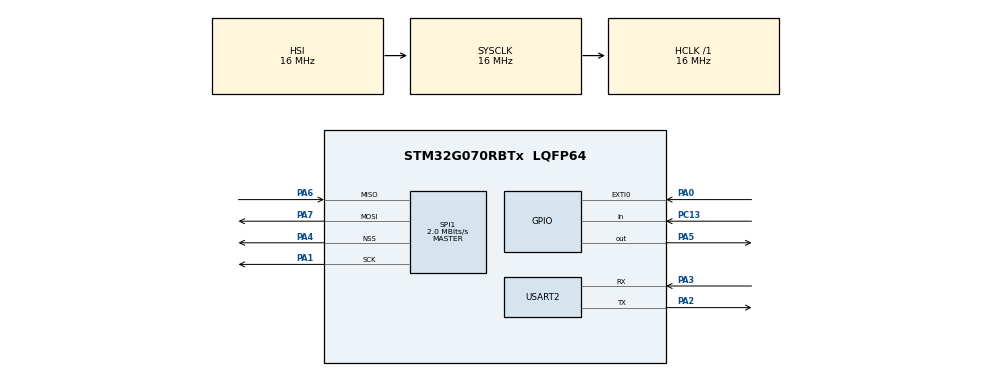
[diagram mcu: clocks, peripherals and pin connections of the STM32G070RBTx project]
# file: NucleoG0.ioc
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Dma.Request0=SPI1_TX
Dma.SPI1_TX.0.Direction=DMA_MEMORY_TO_PERIPH
Dma.SPI1_TX.0.EventEnable=DISABLE
Dma.SPI1_TX.0.Instance=DMA1_Channel1
Dma.SPI1_TX.0.MemDataAlignment=DMA_MDATAALIGN_BYTE
Dma.SPI1_TX.0.MemInc=DMA_MINC_ENABLE
Dma.SPI1_TX.0.Mode=DMA_NORMAL
Dma.SPI1_TX.0.PeriphDataAlignment=DMA_PDATAALIGN_BYTE
Dma.SPI1_TX.0.PeriphInc=DMA_PINC_DISABLE
Dma.SPI1_TX.0.Polarity=HAL_DMAMUX_REQ_GEN_RISING
Dma.SPI1_TX.0.Priority=DMA_PRIORITY_LOW
Dma.SPI1_TX.0.RequestNumber=1
Dma.SPI1_TX.0.SignalID=NONE
Dma.SPI1_TX.0.SyncEnable=DISABLE
Dma.SPI1_TX.0.SyncPolarity=HAL_DMAMUX_SYNC_NO_EVENT
Dma.SPI1_TX.0.SyncRequestNumber=1
Dma.SPI1_TX.0.SyncSignalID=NONE
FREERTOS.INCLUDE_xQueueGetMutexHolder=1
FREERTOS.INCLUDE_xSemaphoreGetMutexHolder=1
FREERTOS.MEMORY_ALLOCATION=0
FREERTOS.Tasks01=defaultTask,0,128,StartDefaultTask,Default,NULL,Dynamic,NULL,NULL
FREERTOS.configTOTAL_HEAP_SIZE=4096
Mcu.Family=STM32G0
Mcu.Name=STM32G070RBTx
Mcu.Package=LQFP64
NVIC.DMA1_Channel1_IRQn=true\:3\:0\:false\:false\:true\:true\:false\:true
NVIC.SPI1_IRQn=true\:3\:0\:false\:false\:true\:true\:true\:true
NVIC.USART2_IRQn=true\:3\:0\:false\:false\:true\:true\:true\:true
PA0.GPIO_PuPd=GPIO_PULLUP
PA0.Signal=GPXTI0
PA1.Mode=Full_Duplex_Master
PA1.Signal=SPI1_SCK
PA2.Mode=Asynchronous
PA2.Signal=USART2_TX
PA3.Mode=Asynchronous
PA3.Signal=USART2_RX
PA4.Mode=NSS_Signal_Hard_Output
PA4.Signal=SPI1_NSS
PA5.Signal=GPIO_Output
PA6.Mode=Full_Duplex_Master
PA6.Signal=SPI1_MISO
PA7.Mode=Full_Duplex_Master
PA7.Signal=SPI1_MOSI
PC13.Signal=GPIO_Input
PC14-OSC32_IN\ (PC14).Mode=LSE-External-Oscillator
PC14-OSC32_IN\ (PC14).Signal=RCC_OSC32_IN
PC15-OSC32_OUT\ (PC15).Mode=LSE-External-Oscillator
PC15-OSC32_OUT\ (PC15).Signal=RCC_OSC32_OUT
PF0-OSC_IN\ (PF0).Mode=HSE-External-Clock-Source
PF0-OSC_IN\ (PF0).Signal=RCC_OSC_IN
ProjectManager.HeapSize=0x200
ProjectManager.StackSize=0x400
ProjectManager.TargetToolchain=STM32CubeIDE
RCC.AHBFreq_Value=16000000
RCC.CortexFreq_Value=16000000
RCC.EXTERNAL_CLOCK_VALUE=48000
RCC.HCLKFreq_Value=16000000
RCC.HSE_VALUE=8000000
RCC.HSI_VALUE=16000000
RCC.SYSCLKFreq_VALUE=16000000
RCC.VCOOutputFreq_Value=128000000
SPI1.BaudRatePrescaler=SPI_BAUDRATEPRESCALER_8
SPI1.CalculateBaudRate=2.0 MBits/s
SPI1.DataSize=SPI_DATASIZE_8BIT
SPI1.Direction=SPI_DIRECTION_2LINES
SPI1.FirstBit=SPI_FIRSTBIT_LSB
SPI1.Mode=SPI_MODE_MASTER
SPI1.VirtualNSS=VM_NSSHARD
SPI1.VirtualType=VM_MASTER
USART2.VirtualMode-Asynchronous=VM_ASYNC
VP_FREERTOS_VS_CMSIS_V1.Mode=CMSIS_V1
VP_SYS_VS_DBSignals.Mode=DisableDeadBatterySignals
board=custom

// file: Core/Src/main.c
/* USER CODE BEGIN Header */
/**
  ******************************************************************************
  * @file           : main.c
  * @brief          : Main program body
  ******************************************************************************
  * @attention
  *
  * <h2><center>&copy; Copyright (c) 2020 STMicroelectronics.
  * All rights reserved.</center></h2>
  *
  * This software component is licensed by ST under BSD 3-Clause license,
  * the "License"; You may not use this file except in compliance with the
  * License. You may obtain a copy of the License at:
  *                        opensource.org/licenses/BSD-3-Clause
  *
  ******************************************************************************
  */
/* USER CODE END Header */

#include "main.h"
#include "cmsis_os.h"

/* USER CODE BEGIN Includes */
#include "application.h"

/* USER CODE END Includes */

/* USER CODE BEGIN PD */
#define LED_GREEN_Pin GPIO_PIN_5
#define LED_GREEN_GPIO_Port GPIOA
/* USER CODE END PD */

SPI_HandleTypeDef hspi1;
DMA_HandleTypeDef hdma_spi1_tx;

UART_HandleTypeDef huart2;

osThreadId defaultTaskHandle;

void SystemClock_Config(void);
static void MX_GPIO_Init(void);
static void MX_DMA_Init(void);
static void MX_USART2_UART_Init(void);
static void MX_SPI1_Init(void);
void StartDefaultTask(void const * argument);

int main(void)
{

  /* MCU Configuration--------------------------------------------------------*/

  /* Reset of all peripherals, Initializes the Flash interface and the Systick. */
  HAL_Init();

  /* Configure the system clock */
  SystemClock_Config();

  /* Initialize all configured peripherals */
  MX_GPIO_Init();
  MX_DMA_Init();
  MX_USART2_UART_Init();
  MX_SPI1_Init();

  /* Create the thread(s) */
  /* definition and creation of defaultTask */
  osThreadDef(defaultTask, StartDefaultTask, osPriorityNormal, 0, 128);
  defaultTaskHandle = osThreadCreate(osThread(defaultTask), NULL);

  /* USER CODE BEGIN RTOS_THREADS */
  application();
  /* add threads, ... */
  /* USER CODE END RTOS_THREADS */

  /* Start scheduler */
  osKernelStart();

  /* We should never get here as control is now taken by the scheduler */
  /* Infinite loop */
  while (1)
  {

  }
}

void SystemClock_Config(void)
{
  RCC_OscInitTypeDef RCC_OscInitStruct = {0};
  RCC_ClkInitTypeDef RCC_ClkInitStruct = {0};
  RCC_PeriphCLKInitTypeDef PeriphClkInit = {0};

  /** Configure the main internal regulator output voltage
  */
  HAL_PWREx_ControlVoltageScaling(PWR_REGULATOR_VOLTAGE_SCALE1);
  /** Initializes the CPU, AHB and APB busses clocks
  */
  RCC_OscInitStruct.OscillatorType = RCC_OSCILLATORTYPE_HSI;
  RCC_OscInitStruct.HSIState = RCC_HSI_ON;
  RCC_OscInitStruct.HSIDiv = RCC_HSI_DIV1;
  RCC_OscInitStruct.HSICalibrationValue = RCC_HSICALIBRATION_DEFAULT;
  RCC_OscInitStruct.PLL.PLLState = RCC_PLL_NONE;
  if (HAL_RCC_OscConfig(&RCC_OscInitStruct) != HAL_OK)
  {
    Error_Handler();
  }
  /** Initializes the CPU, AHB and APB busses clocks
  */
  RCC_ClkInitStruct.ClockType = RCC_CLOCKTYPE_HCLK|RCC_CLOCKTYPE_SYSCLK
                              |RCC_CLOCKTYPE_PCLK1;
  RCC_ClkInitStruct.SYSCLKSource = RCC_SYSCLKSOURCE_HSI;
  RCC_ClkInitStruct.AHBCLKDivider = RCC_SYSCLK_DIV1;
  RCC_ClkInitStruct.APB1CLKDivider = RCC_HCLK_DIV1;

  if (HAL_RCC_ClockConfig(&RCC_ClkInitStruct, FLASH_LATENCY_0) != HAL_OK)
  {
    Error_Handler();
  }
  /** Initializes the peripherals clocks
  */
  PeriphClkInit.PeriphClockSelection = RCC_PERIPHCLK_USART2;
  PeriphClkInit.Usart2ClockSelection = RCC_USART2CLKSOURCE_PCLK1;
  if (HAL_RCCEx_PeriphCLKConfig(&PeriphClkInit) != HAL_OK)
  {
    Error_Handler();
  }
}

static void MX_SPI1_Init(void)
{

  /* SPI1 parameter configuration*/
  hspi1.Instance = SPI1;
  hspi1.Init.Mode = SPI_MODE_MASTER;
  hspi1.Init.Direction = SPI_DIRECTION_2LINES;
  hspi1.Init.DataSize = SPI_DATASIZE_8BIT;
  hspi1.Init.CLKPolarity = SPI_POLARITY_LOW;
  hspi1.Init.CLKPhase = SPI_PHASE_1EDGE;
  hspi1.Init.NSS = SPI_NSS_HARD_OUTPUT;
  hspi1.Init.BaudRatePrescaler = SPI_BAUDRATEPRESCALER_8;
  hspi1.Init.FirstBit = SPI_FIRSTBIT_LSB;
  hspi1.Init.TIMode = SPI_TIMODE_DISABLE;
  hspi1.Init.CRCCalculation = SPI_CRCCALCULATION_DISABLE;
  hspi1.Init.CRCPolynomial = 7;
  hspi1.Init.CRCLength = SPI_CRC_LENGTH_DATASIZE;
  hspi1.Init.NSSPMode = SPI_NSS_PULSE_ENABLE;
  if (HAL_SPI_Init(&hspi1) != HAL_OK)
  {
    Error_Handler();
  }

}

static void MX_USART2_UART_Init(void)
{

  huart2.Instance = USART2;
  huart2.Init.BaudRate = 115200;
  huart2.Init.WordLength = UART_WORDLENGTH_8B;
  huart2.Init.StopBits = UART_STOPBITS_1;
  huart2.Init.Parity = UART_PARITY_NONE;
  huart2.Init.Mode = UART_MODE_TX_RX;
  huart2.Init.HwFlowCtl = UART_HWCONTROL_NONE;
  huart2.Init.OverSampling = UART_OVERSAMPLING_16;
  huart2.Init.OneBitSampling = UART_ONE_BIT_SAMPLE_DISABLE;
  huart2.Init.ClockPrescaler = UART_PRESCALER_DIV1;
  huart2.AdvancedInit.AdvFeatureInit = UART_ADVFEATURE_NO_INIT;
  if (HAL_UART_Init(&huart2) != HAL_OK)
  {
    Error_Handler();
  }
  if (HAL_UARTEx_SetTxFifoThreshold(&huart2, UART_TXFIFO_THRESHOLD_1_8) != HAL_OK)
  {
    Error_Handler();
  }
  if (HAL_UARTEx_SetRxFifoThreshold(&huart2, UART_RXFIFO_THRESHOLD_1_8) != HAL_OK)
  {
    Error_Handler();
  }
  if (HAL_UARTEx_DisableFifoMode(&huart2) != HAL_OK)
  {
    Error_Handler();
  }

}

static void MX_DMA_Init(void)
{

  /* DMA controller clock enable */
  __HAL_RCC_DMA1_CLK_ENABLE();

  /* DMA interrupt init */
  /* DMA1_Channel1_IRQn interrupt configuration */
  HAL_NVIC_SetPriority(DMA1_Channel1_IRQn, 3, 0);
  HAL_NVIC_EnableIRQ(DMA1_Channel1_IRQn);

}

static void MX_GPIO_Init(void)
{
  GPIO_InitTypeDef GPIO_InitStruct = {0};

  /* GPIO Ports Clock Enable */
  __HAL_RCC_GPIOC_CLK_ENABLE();
  __HAL_RCC_GPIOF_CLK_ENABLE();
  __HAL_RCC_GPIOA_CLK_ENABLE();

  /*Configure GPIO pin Output Level */
  HAL_GPIO_WritePin(GPIOA, GPIO_PIN_5, GPIO_PIN_RESET);

  /*Configure GPIO pin : PC13 */
  GPIO_InitStruct.Pin = GPIO_PIN_13;
  GPIO_InitStruct.Mode = GPIO_MODE_INPUT;
  GPIO_InitStruct.Pull = GPIO_NOPULL;
  HAL_GPIO_Init(GPIOC, &GPIO_InitStruct);

  /*Configure GPIO pin : PA0 */
  GPIO_InitStruct.Pin = GPIO_PIN_0;
  GPIO_InitStruct.Mode = GPIO_MODE_IT_RISING;
  GPIO_InitStruct.Pull = GPIO_PULLUP;
  HAL_GPIO_Init(GPIOA, &GPIO_InitStruct);

  /*Configure GPIO pin : PA5 */
  GPIO_InitStruct.Pin = GPIO_PIN_5;
  GPIO_InitStruct.Mode = GPIO_MODE_OUTPUT_PP;
  GPIO_InitStruct.Pull = GPIO_NOPULL;
  GPIO_InitStruct.Speed = GPIO_SPEED_FREQ_LOW;
  HAL_GPIO_Init(GPIOA, &GPIO_InitStruct);

}

void StartDefaultTask(void const * argument)
{
  /* USER CODE BEGIN 5 */
  /* Infinite loop */
  for(;;)
  {
//		HAL_GPIO_WritePin(LED_GREEN_GPIO_Port, LED_GREEN_Pin, GPIO_PIN_RESET);
//		osDelay(500);
//		HAL_GPIO_WritePin(LED_GREEN_GPIO_Port, LED_GREEN_Pin, GPIO_PIN_SET);
		osDelay(500);

  }
  /* USER CODE END 5 */
}

void Error_Handler(void)
{
}

/************************ (C) COPYRIGHT STMicroelectronics *****END OF FILE****/
